# nRF54h20_sysctrl register map
Vendor: Nordic Semiconductor; Series: nRF54h; File version: 1
Registers are 32-bit, read-write, reset 0x0 unless marked. A register's access mark holds for its fields unless they carry their own. Offsets are from the block's base; [hi:lo] are bit positions; lines under a group give offsets from that group; {n}, {i} and the like mark numbered series; 'fields as' and 'values as' point back to an identical list.

## PPIB110 — PPIB registers 0
Base 0x5F098000
Same registers: PPIB120 0x5F8EE000, PPIB121 0x5F8EF000, PPIB130 0x5F925000, PPIB131 0x5F926000, PPIB132 0x5F98D000, PPIB133 0x5F99D000, PPIB134 0x5F9AD000, PPIB135 0x5F9BD000, PPIB136 0x5F9CD000, PPIB137 0x5F9DD000
{0x0+4i} TASKS_SEND[{i}] (i=0..31) wo — Description collection: Enabling SUBSCRIBE_SEND[n] allows an event on the hardwired DPPIC channel to trigger a signal on PPIB channel n. Direct writes to the SEND[n] task are ignored.
  [0] TASKS_SEND — Enabling SUBSCRIBE_SEND[n] allows an event on the hardwired DPPIC channel to trigger a signal on PPIB channel n. Direct writes to the SEND[n] task are ignored.
    1=Trigger task
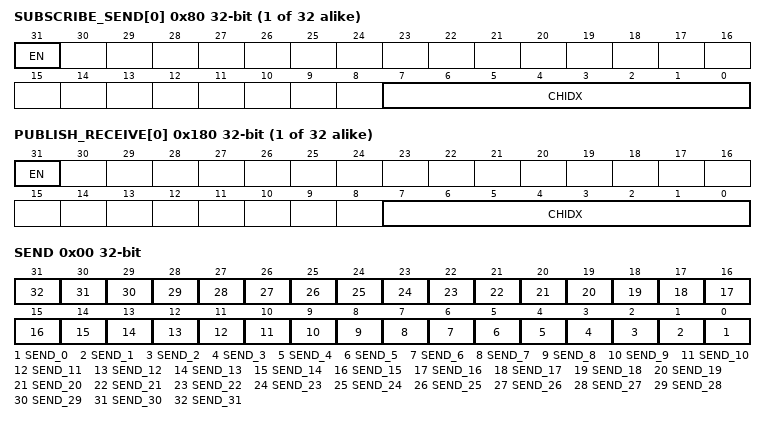
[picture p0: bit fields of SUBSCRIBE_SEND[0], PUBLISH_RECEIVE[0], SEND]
{0x80+4i} SUBSCRIBE_SEND[{i}] (i=0..31) — Description collection: Subscribe configuration for task SEND[n]
  [31] EN
    0=Disabled (Disable subscription); 1=Enabled (Enable subscription)
  [7:0] CHIDX — DPPI channel that task SEND[n] will subscribe to
{0x100+4i} EVENTS_RECEIVE[{i}] (i=0..31) — Description collection: Enabling PUBLISH_RECEIVE[n] allows a signal on PPIB channel n to trigger an event on the hardwired DPPIC channel. Direct reads from the RECEIVE[n] event are ignored.
  [0] EVENTS_RECEIVE — Enabling PUBLISH_RECEIVE[n] allows a signal on PPIB channel n to trigger an event on the hardwired DPPIC channel. Direct reads from the RECEIVE[n] event are ignored.
    0=NotGenerated (Event not generated); 1=Generated (Event generated)
{0x180+4i} PUBLISH_RECEIVE[{i}] (i=0..31) — Description collection: Publish configuration for event RECEIVE[n]
  [31] EN
    0=Disabled (Disable publishing); 1=Enabled (Enable publishing)
  [7:0] CHIDX — DPPI channel that event RECEIVE[n] will publish to
0x400 OVERFLOW group — Unspecified
  0x00 SEND — The task overflow for SEND tasks using SUBSCRIBE_SEND. Write 0 to clear.
    [all] fields
      1=Overflow (Task overflow has happened.); 0=NoOverflow (No task overflow has happened.)
    [n] SEND_{n} (n=0..31) — The status for tasks overflow at SUBSCRIBE_SEND[{n}].

## GLOBAL_SECDOMBELLBOARD — BELLBOARD public registers
Base 0x5F099000
{0x0+4i} TASKS_TRIGGER[{i}] (i=0..31) wo — Description collection: Task TRIGGER[n]
  [0] TASKS_TRIGGER — Task TRIGGER[n]
    1=Trigger task

## MEMCONF120 — Memory configuration 0
Base 0x5F8C7000
Same registers: MEMCONF130 0x5F905000
{0x500+0x10*i} POWER[{i}] (i=0..1) group — Unspecified
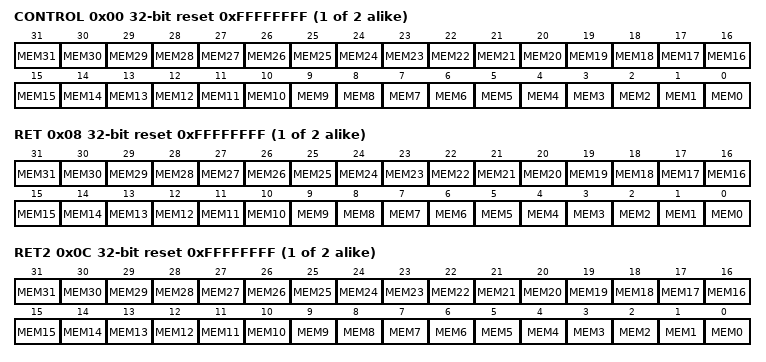
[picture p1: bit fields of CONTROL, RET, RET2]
  0x00 CONTROL reset 0xFFFFFFFF — Description cluster: Control memory section(s) power.
    [all] fields
      0=Off (Unpowered); 1=On (Powered)
    [n] MEM{n} (n=0..31) — Power or unpower the corresponding memory section(s) when the domain the memory is in is powered.
  0x08 RET reset 0xFFFFFFFF — Description cluster: Control memory section(s) retention.
    [all] fields
      0=Off (Not retained); 1=On (Retained)
    [n] MEM{n} (n=0..31) — Retain or do not retain the corresponding memory section(s) when the domain the memory is in is unpowered.
  0x0C RET2 reset 0xFFFFFFFF — Description cluster: Control memory section(s) retention.
    fields as POWER[0].RET
{0x900+4i} BLOCKTYPE[{i}] (i=0..63) group — Unspecified
  0x00 TRIM — Description cluster: Memory trim configuration.
    [31:0] TRIM — Trim value

## GLOBAL_VPR120 — VPR peripheral registers
Base 0x5F8C8000
{0x0+4i} TASKS_TRIGGER[{i}] (i=0..31) wo — Description collection: VPR task [n] register
  [0] TASKS_TRIGGER — VPR task [n] register
    1=Trigger task

## GLOBAL_MUTEX120 — MUTEX 0
Base 0x4F8D2000
Same registers: GLOBAL_MUTEX130 0x4F927000
{0x400+4i} MUTEX[{i}] (i=0..31) — Description collection: Mutex register
  [0] MUTEX — Mutex register n
    0=Unlocked (Mutex n is in unlocked state); 1=Locked (Mutex n is in locked state)
